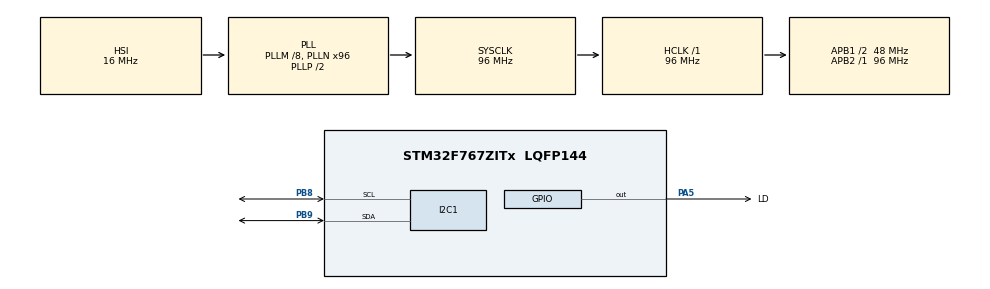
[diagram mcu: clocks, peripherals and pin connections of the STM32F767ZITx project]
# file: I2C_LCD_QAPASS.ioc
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I2C1.Timing=0x20303E5D
Mcu.Family=STM32F7
Mcu.Name=STM32F767ZITx
Mcu.Package=LQFP144
NVIC.PriorityGroup=NVIC_PRIORITYGROUP_4
PA13.Mode=Serial_Wire
PA13.Signal=SYS_JTMS-SWDIO
PA14.Mode=Serial_Wire
PA14.Signal=SYS_JTCK-SWCLK
PA5.GPIO_Label=LD
PA5.Signal=GPIO_Output
PB8.Mode=I2C
PB8.Signal=I2C1_SCL
PB9.Mode=I2C
PB9.Signal=I2C1_SDA
PH0/OSC_IN.Mode=HSE-External-Oscillator
PH0/OSC_IN.Signal=RCC_OSC_IN
PH1/OSC_OUT.Mode=HSE-External-Oscillator
PH1/OSC_OUT.Signal=RCC_OSC_OUT
ProjectManager.HeapSize=0x200
ProjectManager.StackSize=0x400
ProjectManager.TargetToolchain=TrueSTUDIO
RCC.48MHZClocksFreq_Value=24000000
RCC.AHBFreq_Value=96000000
RCC.APB1CLKDivider=RCC_HCLK_DIV2
RCC.APB1Freq_Value=48000000
RCC.APB1TimFreq_Value=96000000
RCC.APB2Freq_Value=96000000
RCC.APB2TimFreq_Value=96000000
RCC.CortexFreq_Value=96000000
RCC.HCLKFreq_Value=96000000
RCC.HSE_VALUE=8000000
RCC.HSI_VALUE=16000000
RCC.LSE_VALUE=32768
RCC.PLLM=8
RCC.PLLMUL=RCC_PLL_MUL9
RCC.PLLN=96
RCC.PLLQ=4
RCC.PRESCALERUSB=RCC_USBCLKSOURCE_PLL_DIV1_5
RCC.SYSCLKFreq_VALUE=96000000
RCC.SYSCLKSource=RCC_SYSCLKSOURCE_PLLCLK
RCC.SYSCLKSourceVirtual=RCC_SYSCLKSOURCE_PLLCLK
RCC.USBFreq_Value=48000000
RCC.VCOOutputFreq_Value=192000000
board=NUCLEO-F767ZI

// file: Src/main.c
/* USER CODE BEGIN Header */
/**
  ******************************************************************************
  * @file           : main.c
  * @brief          : Main program body
  ******************************************************************************
  * @attention
  *
  * <h2><center>&copy; Copyright (c) 2019 STMicroelectronics.
  * All rights reserved.</center></h2>
  *
  * This software component is licensed by ST under BSD 3-Clause license,
  * the "License"; You may not use this file except in compliance with the
  * License. You may obtain a copy of the License at:
  *                        opensource.org/licenses/BSD-3-Clause
  *
  ******************************************************************************
  */
/* USER CODE END Header */

#include "main.h"

I2C_HandleTypeDef hi2c1;

/* USER CODE BEGIN PV */
#define SI7021Adress 0x80
#define LCDAdress 0x4E
/* USER CODE END PV */

void SystemClock_Config(void);
static void MX_GPIO_Init(void);
static void MX_I2C1_Init(void);

/* USER CODE BEGIN 0 */

/*explication ds la video youtube de controllers Tech*/
void lcd_send_cmd(char cmd)
{
char data_u, data_l;
uint8_t data_t[4];
data_u = cmd&0xf0;
data_l = (cmd<<4)&0xf0;
data_t[0] = data_u | 0x04;
data_t[1] = data_u;
data_t[2] = data_l |0x04;
data_t[3] = data_l ;

HAL_I2C_Master_Transmit(&hi2c1,LCDAdress,(uint8_t*)data_t,4,100);
}

void lcd_send_data(char data)
{

char data_u, data_l;
uint8_t data_t[4];
data_u = data&0xf0;
data_l = (data<<4)&0xf0;
data_t[0] = data_u|0x05;
data_t[1] = data_u|0x01;
data_t[2] = data_l|0x05;
data_t[3] = data_l|0x01;

HAL_I2C_Master_Transmit(&hi2c1,LCDAdress,(uint8_t*)data_t,4,100);

}

void lcd_init()
{
 lcd_send_cmd(0x02);
 lcd_send_cmd(0x28);
 lcd_send_cmd(0x0c);
 lcd_send_cmd(0x80);
}

void lcd_send_string(char *str)
{

while (*str) lcd_send_data(*str++);
}

char num[]={'0','1','2','3','4','5'};
uint8_t i2cBuff[2];
/* USER CODE END 0 */

int main(void)
{

  /* MCU Configuration--------------------------------------------------------*/

  /* Reset of all peripherals, Initializes the Flash interface and the Systick. */
  HAL_Init();

  /* Configure the system clock */
  SystemClock_Config();

  /* Initialize all configured peripherals */
  MX_GPIO_Init();
  MX_I2C1_Init();
  /* USER CODE BEGIN 2 */

  lcd_init(); // init lcd

  lcd_send_cmd(0x80); // cursor to 1 row und 1 col

  //lcd_send_string("Hallo was willst du ?");

/* comment scanner pour avoir le slave adress*/

/*  for(uint8_t i=0; i<255; i++)
  {
	  if(HAL_I2C_IsDeviceReady(&hi2c1,i,1,10)==HAL_OK)
	  {
		  HAL_GPIO_TogglePin(LD_GPIO_Port,LD_Pin);
		  break;
	  }

  }*/

  /* USER CODE END 2 */

  /* Infinite loop */
  while (1)
  {

    /* USER CODE BEGIN 3 */

//compter les numbres....
/*	  for(uint8_t i=0;i<6;i++)
	  {
		  lcd_send_data(num[i]);
		  HAL_Delay(1000);
		  lcd_send_cmd(0x80);
	  }*/
	  lcd_send_cmd(0x80); //goto 1,1
	  lcd_send_string("NAEL & INAYA");
	  lcd_send_cmd(0xC0);//goto 2,1?
	  lcd_send_string("Mes BEBES !!!");
	  HAL_Delay(2000);
	  lcd_send_cmd(0x01);// clear display
	  HAL_Delay(1000);

  }
  /* USER CODE END 3 */
}

void SystemClock_Config(void)
{
  RCC_OscInitTypeDef RCC_OscInitStruct = {0};
  RCC_ClkInitTypeDef RCC_ClkInitStruct = {0};
  RCC_PeriphCLKInitTypeDef PeriphClkInitStruct = {0};

  /** Configure the main internal regulator output voltage
  */
  __HAL_RCC_PWR_CLK_ENABLE();
  __HAL_PWR_VOLTAGESCALING_CONFIG(PWR_REGULATOR_VOLTAGE_SCALE3);
  /** Initializes the CPU, AHB and APB busses clocks
  */
  RCC_OscInitStruct.OscillatorType = RCC_OSCILLATORTYPE_HSI;
  RCC_OscInitStruct.HSIState = RCC_HSI_ON;
  RCC_OscInitStruct.HSICalibrationValue = RCC_HSICALIBRATION_DEFAULT;
  RCC_OscInitStruct.PLL.PLLState = RCC_PLL_ON;
  RCC_OscInitStruct.PLL.PLLSource = RCC_PLLSOURCE_HSI;
  RCC_OscInitStruct.PLL.PLLM = 8;
  RCC_OscInitStruct.PLL.PLLN = 96;
  RCC_OscInitStruct.PLL.PLLP = RCC_PLLP_DIV2;
  RCC_OscInitStruct.PLL.PLLQ = 4;
  if (HAL_RCC_OscConfig(&RCC_OscInitStruct) != HAL_OK)
  {
    Error_Handler();
  }
  /** Activate the Over-Drive mode
  */
  if (HAL_PWREx_EnableOverDrive() != HAL_OK)
  {
    Error_Handler();
  }
  /** Initializes the CPU, AHB and APB busses clocks
  */
  RCC_ClkInitStruct.ClockType = RCC_CLOCKTYPE_HCLK|RCC_CLOCKTYPE_SYSCLK
                              |RCC_CLOCKTYPE_PCLK1|RCC_CLOCKTYPE_PCLK2;
  RCC_ClkInitStruct.SYSCLKSource = RCC_SYSCLKSOURCE_PLLCLK;
  RCC_ClkInitStruct.AHBCLKDivider = RCC_SYSCLK_DIV1;
  RCC_ClkInitStruct.APB1CLKDivider = RCC_HCLK_DIV2;
  RCC_ClkInitStruct.APB2CLKDivider = RCC_HCLK_DIV1;

  if (HAL_RCC_ClockConfig(&RCC_ClkInitStruct, FLASH_LATENCY_3) != HAL_OK)
  {
    Error_Handler();
  }
  PeriphClkInitStruct.PeriphClockSelection = RCC_PERIPHCLK_I2C1;
  PeriphClkInitStruct.I2c1ClockSelection = RCC_I2C1CLKSOURCE_PCLK1;
  if (HAL_RCCEx_PeriphCLKConfig(&PeriphClkInitStruct) != HAL_OK)
  {
    Error_Handler();
  }
}

static void MX_I2C1_Init(void)
{

  hi2c1.Instance = I2C1;
  hi2c1.Init.Timing = 0x20303E5D;
  hi2c1.Init.OwnAddress1 = 0;
  hi2c1.Init.AddressingMode = I2C_ADDRESSINGMODE_7BIT;
  hi2c1.Init.DualAddressMode = I2C_DUALADDRESS_DISABLE;
  hi2c1.Init.OwnAddress2 = 0;
  hi2c1.Init.OwnAddress2Masks = I2C_OA2_NOMASK;
  hi2c1.Init.GeneralCallMode = I2C_GENERALCALL_DISABLE;
  hi2c1.Init.NoStretchMode = I2C_NOSTRETCH_DISABLE;
  if (HAL_I2C_Init(&hi2c1) != HAL_OK)
  {
    Error_Handler();
  }
  /** Configure Analogue filter
  */
  if (HAL_I2CEx_ConfigAnalogFilter(&hi2c1, I2C_ANALOGFILTER_ENABLE) != HAL_OK)
  {
    Error_Handler();
  }
  /** Configure Digital filter
  */
  if (HAL_I2CEx_ConfigDigitalFilter(&hi2c1, 0) != HAL_OK)
  {
    Error_Handler();
  }

}

static void MX_GPIO_Init(void)
{
  GPIO_InitTypeDef GPIO_InitStruct = {0};

  /* GPIO Ports Clock Enable */
  __HAL_RCC_GPIOH_CLK_ENABLE();
  __HAL_RCC_GPIOA_CLK_ENABLE();
  __HAL_RCC_GPIOB_CLK_ENABLE();

  /*Configure GPIO pin Output Level */
  HAL_GPIO_WritePin(LD_GPIO_Port, LD_Pin, GPIO_PIN_RESET);

  /*Configure GPIO pin : LD_Pin */
  GPIO_InitStruct.Pin = LD_Pin;
  GPIO_InitStruct.Mode = GPIO_MODE_OUTPUT_PP;
  GPIO_InitStruct.Pull = GPIO_NOPULL;
  GPIO_InitStruct.Speed = GPIO_SPEED_FREQ_LOW;
  HAL_GPIO_Init(LD_GPIO_Port, &GPIO_InitStruct);

}

void Error_Handler(void)
{
}

/************************ (C) COPYRIGHT STMicroelectronics *****END OF FILE****/
